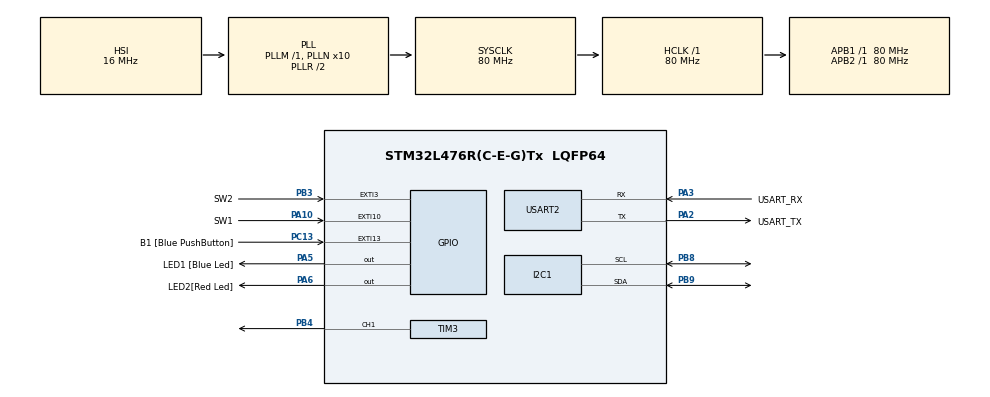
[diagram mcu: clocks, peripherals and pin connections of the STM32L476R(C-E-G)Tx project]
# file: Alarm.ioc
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FREERTOS.Tasks01=defaultTas,24,128,Default,As weak,NULL,Dynamic,NULL,NULL;buzzerTask,8,384,Buzzer_playTask,As external,&bz1,Dynamic,NULL,NULL;comTask,8,256,Communication_handleTask,As external,NULL,Dynamic,NULL,NULL;alarmTask,8,384,Alarm_startTask,As external,&rtc1,Dynamic,NULL,NULL;blinkTaskRed,8,128,Led_blinkTask,As external,&ledR,Dynamic,NULL,NULL;blinkTaskBlue,8,128,Led_blinkTask,As external,&ledB,Dynamic,NULL,NULL;buttonTask1,8,256,Button_pressTask,As external,&btn1,Dynamic,NULL,NULL;buttonTask2,8,256,Button_pressTask,As external,&btn2,Dynamic,NULL,NULL
FREERTOS.configTOTAL_HEAP_SIZE=9000
I2C1.Timing=0x10909CEC
Mcu.Family=STM32L4
Mcu.Name=STM32L476R(C-E-G)Tx
Mcu.Package=LQFP64
NVIC.PriorityGroup=NVIC_PRIORITYGROUP_4
NVIC.TIM1_UP_TIM16_IRQn=true\:15\:0\:false\:false\:true\:false\:false\:true\:true
NVIC.TimeBase=TIM1_UP_TIM16_IRQn
NVIC.TimeBaseIP=TIM16
PA10.GPIO_Label=SW1
PA10.Signal=GPXTI10
PA13\ (JTMS-SWDIO).GPIO_Label=TMS
PA13\ (JTMS-SWDIO).Mode=Serial_Wire
PA13\ (JTMS-SWDIO).Signal=SYS_JTMS-SWDIO
PA14\ (JTCK-SWCLK).GPIO_Label=TCK
PA14\ (JTCK-SWCLK).Mode=Serial_Wire
PA14\ (JTCK-SWCLK).Signal=SYS_JTCK-SWCLK
PA2.GPIO_Label=USART_TX
PA2.GPIO_Mode=GPIO_MODE_AF_PP
PA2.GPIO_PuPd=GPIO_NOPULL
PA2.GPIO_Speed=GPIO_SPEED_FREQ_VERY_HIGH
PA2.Mode=Asynchronous
PA2.Signal=USART2_TX
PA3.GPIO_Label=USART_RX
PA3.GPIO_Mode=GPIO_MODE_AF_PP
PA3.GPIO_PuPd=GPIO_NOPULL
PA3.GPIO_Speed=GPIO_SPEED_FREQ_VERY_HIGH
PA3.Mode=Asynchronous
PA3.Signal=USART2_RX
PA5.GPIO_Label=LED1 [Blue Led]
PA5.GPIO_ModeDefaultOutputPP=GPIO_MODE_OUTPUT_PP
PA5.GPIO_PuPd=GPIO_NOPULL
PA5.GPIO_Speed=GPIO_SPEED_FREQ_LOW
PA5.Signal=GPIO_Output
PA6.GPIO_Label=LED2[Red Led]
PA6.Signal=GPIO_Output
PB3\ (JTDO-TRACESWO).GPIO_Label=SW2
PB3\ (JTDO-TRACESWO).Signal=GPXTI3
PB4\ (NJTRST).Signal=S_TIM3_CH1
PB8.Mode=I2C
PB8.Signal=I2C1_SCL
PB9.Mode=I2C
PB9.Signal=I2C1_SDA
PC13.GPIO_Label=B1 [Blue PushButton]
PC13.GPIO_ModeDefaultEXTI=GPIO_MODE_IT_FALLING
PC13.GPIO_PuPd=GPIO_NOPULL
PC13.Signal=GPXTI13
PC14-OSC32_IN\ (PC14).Mode=LSE-External-Oscillator
PC14-OSC32_IN\ (PC14).Signal=RCC_OSC32_IN
PC15-OSC32_OUT\ (PC15).Mode=LSE-External-Oscillator
PC15-OSC32_OUT\ (PC15).Signal=RCC_OSC32_OUT
PH0-OSC_IN\ (PH0).Signal=RCC_OSC_IN
PH1-OSC_OUT\ (PH1).Signal=RCC_OSC_OUT
ProjectManager.HeapSize=0x200
ProjectManager.StackSize=0x400
ProjectManager.TargetToolchain=STM32CubeIDE
RCC.ADCFreq_Value=64000000
RCC.AHBFreq_Value=80000000
RCC.APB1Freq_Value=80000000
RCC.APB1TimFreq_Value=80000000
RCC.APB2Freq_Value=80000000
RCC.APB2TimFreq_Value=80000000
RCC.CortexFreq_Value=80000000
RCC.HCLKFreq_Value=80000000
RCC.HSE_VALUE=8000000
RCC.HSI_VALUE=16000000
RCC.MSI_VALUE=4000000
RCC.PLLN=10
RCC.PLLSourceVirtual=RCC_PLLSOURCE_HSI
RCC.PREFETCH_ENABLE=1
RCC.SYSCLKFreq_VALUE=80000000
RCC.SYSCLKSource=RCC_SYSCLKSOURCE_PLLCLK
RCC.USBFreq_Value=64000000
RCC.VCOOutputFreq_Value=160000000
SH.S_TIM3_CH1.0=TIM3_CH1,PWM Generation1 CH1
TIM3.Channel-PWM\ Generation1\ CH1=TIM_CHANNEL_1
TIM3.Period=392
TIM3.Prescaler=799
TIM3.Pulse-PWM\ Generation1\ CH1=0
USART2.VirtualMode-Asynchronous=VM_ASYNC
VP_FREERTOS_VS_CMSIS_V2.Mode=CMSIS_V2
VP_SYS_VS_tim16.Mode=TIM16
board=NUCLEO-L476RG

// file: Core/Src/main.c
/* USER CODE BEGIN Header */
/**
  ******************************************************************************
  * @file           : main.c
  * @brief          : Main program body
  ******************************************************************************
  * @attention
  *
  * Copyright (c) 2022 STMicroelectronics.
  * All rights reserved.
  *
  * This software is licensed under terms that can be found in the LICENSE file
  * in the root directory of this software component.
  * If no LICENSE file comes with this software, it is provided AS-IS.
  *
  ******************************************************************************
  */
/* USER CODE END Header */
#include "main.h"
#include "cmsis_os.h"

/* USER CODE BEGIN Includes */
#include "MyMain.h"
/* USER CODE END Includes */

 I2C_HandleTypeDef hi2c1;

TIM_HandleTypeDef htim3;

UART_HandleTypeDef huart2;

/* Definitions for defaultTas */
osThreadId_t defaultTasHandle;
const osThreadAttr_t defaultTas_attributes = {
  .name = "defaultTas",
  .stack_size = 128 * 4,
  .priority = (osPriority_t) osPriorityNormal,
};
/* Definitions for buzzerTask */
osThreadId_t buzzerTaskHandle;
const osThreadAttr_t buzzerTask_attributes = {
  .name = "buzzerTask",
  .stack_size = 384 * 4,
  .priority = (osPriority_t) osPriorityLow,
};
/* Definitions for comTask */
osThreadId_t comTaskHandle;
const osThreadAttr_t comTask_attributes = {
  .name = "comTask",
  .stack_size = 256 * 4,
  .priority = (osPriority_t) osPriorityLow,
};
/* Definitions for alarmTask */
osThreadId_t alarmTaskHandle;
const osThreadAttr_t alarmTask_attributes = {
  .name = "alarmTask",
  .stack_size = 384 * 4,
  .priority = (osPriority_t) osPriorityLow,
};
/* Definitions for blinkTaskRed */
osThreadId_t blinkTaskRedHandle;
const osThreadAttr_t blinkTaskRed_attributes = {
  .name = "blinkTaskRed",
  .stack_size = 128 * 4,
  .priority = (osPriority_t) osPriorityLow,
};
/* Definitions for blinkTaskBlue */
osThreadId_t blinkTaskBlueHandle;
const osThreadAttr_t blinkTaskBlue_attributes = {
  .name = "blinkTaskBlue",
  .stack_size = 128 * 4,
  .priority = (osPriority_t) osPriorityLow,
};
/* Definitions for buttonTask1 */
osThreadId_t buttonTask1Handle;
const osThreadAttr_t buttonTask1_attributes = {
  .name = "buttonTask1",
  .stack_size = 256 * 4,
  .priority = (osPriority_t) osPriorityLow,
};
/* Definitions for buttonTask2 */
osThreadId_t buttonTask2Handle;
const osThreadAttr_t buttonTask2_attributes = {
  .name = "buttonTask2",
  .stack_size = 256 * 4,
  .priority = (osPriority_t) osPriorityLow,
};

void SystemClock_Config(void);
static void MX_GPIO_Init(void);
static void MX_USART2_UART_Init(void);
static void MX_TIM3_Init(void);
static void MX_I2C1_Init(void);
void Default(void *argument);
extern void Buzzer_playTask(void *argument);
extern void Communication_handleTask(void *argument);
extern void Alarm_startTask(void *argument);
extern void Led_blinkTask(void *argument);
extern void Button_pressTask(void *argument);

int main(void)
{

  /* MCU Configuration--------------------------------------------------------*/

  /* Reset of all peripherals, Initializes the Flash interface and the Systick. */
  HAL_Init();

  /* Configure the system clock */
  SystemClock_Config();

  /* Initialize all configured peripherals */
  MX_GPIO_Init();
  MX_USART2_UART_Init();
  MX_TIM3_Init();
  MX_I2C1_Init();
  /* USER CODE BEGIN 2 */
  MyMain();
  /* USER CODE END 2 */

  /* Init scheduler */
  osKernelInitialize();

  /* Create the thread(s) */
  /* creation of defaultTas */
  defaultTasHandle = osThreadNew(Default, NULL, &defaultTas_attributes);

  /* creation of buzzerTask */
  buzzerTaskHandle = osThreadNew(Buzzer_playTask, (void*) &bz1, &buzzerTask_attributes);

  /* creation of comTask */
  comTaskHandle = osThreadNew(Communication_handleTask, NULL, &comTask_attributes);

  /* creation of alarmTask */
  alarmTaskHandle = osThreadNew(Alarm_startTask, (void*) &rtc1, &alarmTask_attributes);

  /* creation of blinkTaskRed */
  blinkTaskRedHandle = osThreadNew(Led_blinkTask, (void*) &ledR, &blinkTaskRed_attributes);

  /* creation of blinkTaskBlue */
  blinkTaskBlueHandle = osThreadNew(Led_blinkTask, (void*) &ledB, &blinkTaskBlue_attributes);

  /* creation of buttonTask1 */
  buttonTask1Handle = osThreadNew(Button_pressTask, (void*) &btn1, &buttonTask1_attributes);

  /* creation of buttonTask2 */
  buttonTask2Handle = osThreadNew(Button_pressTask, (void*) &btn2, &buttonTask2_attributes);

  /* Start scheduler */
  osKernelStart();

  /* We should never get here as control is now taken by the scheduler */
  /* Infinite loop */
  while (1)
  {

  }
}

void SystemClock_Config(void)
{
  RCC_OscInitTypeDef RCC_OscInitStruct = {0};
  RCC_ClkInitTypeDef RCC_ClkInitStruct = {0};

  /** Configure the main internal regulator output voltage
  */
  if (HAL_PWREx_ControlVoltageScaling(PWR_REGULATOR_VOLTAGE_SCALE1) != HAL_OK)
  {
    Error_Handler();
  }

  /** Initializes the RCC Oscillators according to the specified parameters
  * in the RCC_OscInitTypeDef structure.
  */
  RCC_OscInitStruct.OscillatorType = RCC_OSCILLATORTYPE_HSI;
  RCC_OscInitStruct.HSIState = RCC_HSI_ON;
  RCC_OscInitStruct.HSICalibrationValue = RCC_HSICALIBRATION_DEFAULT;
  RCC_OscInitStruct.PLL.PLLState = RCC_PLL_ON;
  RCC_OscInitStruct.PLL.PLLSource = RCC_PLLSOURCE_HSI;
  RCC_OscInitStruct.PLL.PLLM = 1;
  RCC_OscInitStruct.PLL.PLLN = 10;
  RCC_OscInitStruct.PLL.PLLP = RCC_PLLP_DIV7;
  RCC_OscInitStruct.PLL.PLLQ = RCC_PLLQ_DIV2;
  RCC_OscInitStruct.PLL.PLLR = RCC_PLLR_DIV2;
  if (HAL_RCC_OscConfig(&RCC_OscInitStruct) != HAL_OK)
  {
    Error_Handler();
  }

  /** Initializes the CPU, AHB and APB buses clocks
  */
  RCC_ClkInitStruct.ClockType = RCC_CLOCKTYPE_HCLK|RCC_CLOCKTYPE_SYSCLK
                              |RCC_CLOCKTYPE_PCLK1|RCC_CLOCKTYPE_PCLK2;
  RCC_ClkInitStruct.SYSCLKSource = RCC_SYSCLKSOURCE_PLLCLK;
  RCC_ClkInitStruct.AHBCLKDivider = RCC_SYSCLK_DIV1;
  RCC_ClkInitStruct.APB1CLKDivider = RCC_HCLK_DIV1;
  RCC_ClkInitStruct.APB2CLKDivider = RCC_HCLK_DIV1;

  if (HAL_RCC_ClockConfig(&RCC_ClkInitStruct, FLASH_LATENCY_4) != HAL_OK)
  {
    Error_Handler();
  }
}

static void MX_I2C1_Init(void)
{

  hi2c1.Instance = I2C1;
  hi2c1.Init.Timing = 0x10909CEC;
  hi2c1.Init.OwnAddress1 = 0;
  hi2c1.Init.AddressingMode = I2C_ADDRESSINGMODE_7BIT;
  hi2c1.Init.DualAddressMode = I2C_DUALADDRESS_DISABLE;
  hi2c1.Init.OwnAddress2 = 0;
  hi2c1.Init.OwnAddress2Masks = I2C_OA2_NOMASK;
  hi2c1.Init.GeneralCallMode = I2C_GENERALCALL_DISABLE;
  hi2c1.Init.NoStretchMode = I2C_NOSTRETCH_DISABLE;
  if (HAL_I2C_Init(&hi2c1) != HAL_OK)
  {
    Error_Handler();
  }

  /** Configure Analogue filter
  */
  if (HAL_I2CEx_ConfigAnalogFilter(&hi2c1, I2C_ANALOGFILTER_ENABLE) != HAL_OK)
  {
    Error_Handler();
  }

  /** Configure Digital filter
  */
  if (HAL_I2CEx_ConfigDigitalFilter(&hi2c1, 0) != HAL_OK)
  {
    Error_Handler();
  }

}

static void MX_TIM3_Init(void)
{

  TIM_MasterConfigTypeDef sMasterConfig = {0};
  TIM_OC_InitTypeDef sConfigOC = {0};

  htim3.Instance = TIM3;
  htim3.Init.Prescaler = 799;
  htim3.Init.CounterMode = TIM_COUNTERMODE_UP;
  htim3.Init.Period = 392;
  htim3.Init.ClockDivision = TIM_CLOCKDIVISION_DIV1;
  htim3.Init.AutoReloadPreload = TIM_AUTORELOAD_PRELOAD_DISABLE;
  if (HAL_TIM_PWM_Init(&htim3) != HAL_OK)
  {
    Error_Handler();
  }
  sMasterConfig.MasterOutputTrigger = TIM_TRGO_RESET;
  sMasterConfig.MasterSlaveMode = TIM_MASTERSLAVEMODE_DISABLE;
  if (HAL_TIMEx_MasterConfigSynchronization(&htim3, &sMasterConfig) != HAL_OK)
  {
    Error_Handler();
  }
  sConfigOC.OCMode = TIM_OCMODE_PWM1;
  sConfigOC.Pulse = 0;
  sConfigOC.OCPolarity = TIM_OCPOLARITY_HIGH;
  sConfigOC.OCFastMode = TIM_OCFAST_DISABLE;
  if (HAL_TIM_PWM_ConfigChannel(&htim3, &sConfigOC, TIM_CHANNEL_1) != HAL_OK)
  {
    Error_Handler();
  }
  HAL_TIM_MspPostInit(&htim3);

}

static void MX_USART2_UART_Init(void)
{

  huart2.Instance = USART2;
  huart2.Init.BaudRate = 115200;
  huart2.Init.WordLength = UART_WORDLENGTH_8B;
  huart2.Init.StopBits = UART_STOPBITS_1;
  huart2.Init.Parity = UART_PARITY_NONE;
  huart2.Init.Mode = UART_MODE_TX_RX;
  huart2.Init.HwFlowCtl = UART_HWCONTROL_NONE;
  huart2.Init.OverSampling = UART_OVERSAMPLING_16;
  huart2.Init.OneBitSampling = UART_ONE_BIT_SAMPLE_DISABLE;
  huart2.AdvancedInit.AdvFeatureInit = UART_ADVFEATURE_NO_INIT;
  if (HAL_UART_Init(&huart2) != HAL_OK)
  {
    Error_Handler();
  }

}

static void MX_GPIO_Init(void)
{
  GPIO_InitTypeDef GPIO_InitStruct = {0};

  /* GPIO Ports Clock Enable */
  __HAL_RCC_GPIOC_CLK_ENABLE();
  __HAL_RCC_GPIOH_CLK_ENABLE();
  __HAL_RCC_GPIOA_CLK_ENABLE();
  __HAL_RCC_GPIOB_CLK_ENABLE();

  /*Configure GPIO pin Output Level */
  HAL_GPIO_WritePin(GPIOA, LED1_Pin|LED2_Pin, GPIO_PIN_RESET);

  /*Configure GPIO pin : B1_Pin */
  GPIO_InitStruct.Pin = B1_Pin;
  GPIO_InitStruct.Mode = GPIO_MODE_IT_FALLING;
  GPIO_InitStruct.Pull = GPIO_NOPULL;
  HAL_GPIO_Init(B1_GPIO_Port, &GPIO_InitStruct);

  /*Configure GPIO pins : LED1_Pin LED2_Pin */
  GPIO_InitStruct.Pin = LED1_Pin|LED2_Pin;
  GPIO_InitStruct.Mode = GPIO_MODE_OUTPUT_PP;
  GPIO_InitStruct.Pull = GPIO_NOPULL;
  GPIO_InitStruct.Speed = GPIO_SPEED_FREQ_LOW;
  HAL_GPIO_Init(GPIOA, &GPIO_InitStruct);

  /*Configure GPIO pin : SW1_Pin */
  GPIO_InitStruct.Pin = SW1_Pin;
  GPIO_InitStruct.Mode = GPIO_MODE_IT_RISING;
  GPIO_InitStruct.Pull = GPIO_NOPULL;
  HAL_GPIO_Init(SW1_GPIO_Port, &GPIO_InitStruct);

  /*Configure GPIO pin : SW2_Pin */
  GPIO_InitStruct.Pin = SW2_Pin;
  GPIO_InitStruct.Mode = GPIO_MODE_IT_RISING;
  GPIO_InitStruct.Pull = GPIO_NOPULL;
  HAL_GPIO_Init(SW2_GPIO_Port, &GPIO_InitStruct);

}

/* USER CODE BEGIN 4 */
int _write(int fd, char* ptr, int len) {
    HAL_UART_Transmit(&huart2, (uint8_t *) ptr, len, HAL_MAX_DELAY);
    return len;
}
/* USER CODE END 4 */

__weak void Default(void *argument)
{
  for(;;)
  {
    osDelay(1);
  }
}

void HAL_TIM_PeriodElapsedCallback(TIM_HandleTypeDef *htim)
{
  if (htim->Instance == TIM16) {
    HAL_IncTick();
  }
}

void Error_Handler(void)
{
  __disable_irq();
  while (1)
  {
  }
}
